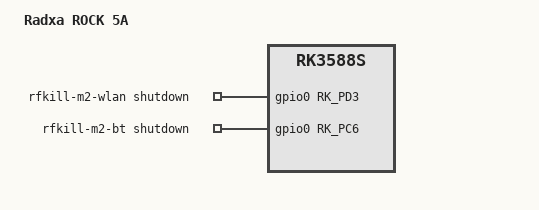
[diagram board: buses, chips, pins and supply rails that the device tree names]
// SPDX-License-Identifier: (GPL-2.0+ OR MIT)
/*
 * Copyright (c) 2024 Radxa Computer (Shenzhen) Co., Ltd.
 */

/dts-v1/;

#include "rk3588s-rock-5.dtsi"

/ {
	model = "Radxa ROCK 5A";
	compatible = "radxa,rock-5a", "rockchip,rk3588s";

	hdmi0-con {
		type = "d";
	};

	regulator-vbus-typec {
		regulator-min-microvolt = <12000000>;
		regulator-max-microvolt = <12000000>;
	};

	rfkill {
		compatible = "rfkill-gpio";
		label = "rfkill-m2-wlan";
		radio-type = "wlan";
		shutdown-gpios = <&gpio0 RK_PD3 GPIO_ACTIVE_HIGH>;
	};

	rfkill-bt {
		compatible = "rfkill-gpio";
		label = "rfkill-m2-bt";
		radio-type = "bluetooth";
		shutdown-gpios = <&gpio0 RK_PC6 GPIO_ACTIVE_HIGH>;
	};
};
